AUTOSAR XML (schema 00046)
package /Composite_SWC
  sender receiver interface Light_Control
    data Light_Data: type=uint32
  sender receiver interface Light_Actuate
    data Light_Control_Decision: type=uint32
  sensor actuator sw component type LightControl_SWC
    provide port PP_LightData: provided-interface=Light_Control
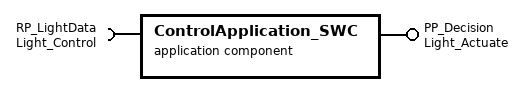
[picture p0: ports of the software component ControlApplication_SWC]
  application sw component type ControlApplication_SWC
    require port RP_LightData: required-interface=Light_Control
    provide port PP_Decision: provided-interface=Light_Actuate
  sensor actuator sw component type LightActuate_SWC
    require port RP_Decision: required-interface=Light_Actuate
  composition sw component type Composite1
    provide port PP_Decision_Comp1: provided-interface=Light_Actuate
    component LightControl_SWC_Instance: type=LightControl_SWC
    component ControlApplication_SWC_Instance: type=ControlApplication_SWC
    connect LightControl_SWC_Instance.PP_LightData -> ControlApplication_SWC_Instance.RP_Decision
    delegate ControlApplication_SWC_Instance.Light_Actuate <-> outer port PP_Decision_Comp1
  composition sw component type Top_Level_Composite
    component Composite1_Instance: type=Composite1
    component LightActuate_SWC_Instance: type=LightActuate_SWC
    connect ControlApplication_SWC_Instance.PP_Decision -> LightActuate_SWC_Instance.RP_Decision
